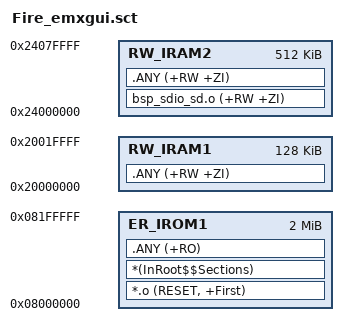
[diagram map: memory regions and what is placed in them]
; *************************************************************
; *** Scatter-Loading Description File generated by uVision ***
; *************************************************************

LR_IROM1 0x08000000 0x00200000  {    ; load region size_region
  ER_IROM1 0x08000000 0x00200000  {  ; load address = execution address
   *.o (RESET, +First)
   *(InRoot$$Sections)
   .ANY (+RO)
  }
  ;ER_IROM2 0x00000000 0x00010000  {  ; load address = execution address
    ;K6502.o(+RO)
    ;InfoNES.o(+RO)
    ;InfoNES_pAPU.o(+RO)
    ;GUI_NES_Dialog.o(+RO)
  ;}  
  RW_IRAM1 0x20000000 0x00020000  {  ; RW data
   .ANY (+RW +ZI)
  }
  RW_IRAM2 0x24000000 0x00080000  {
   bsp_sdio_sd.o (+RW +ZI)
   .ANY (+RW +ZI)
  }
}

